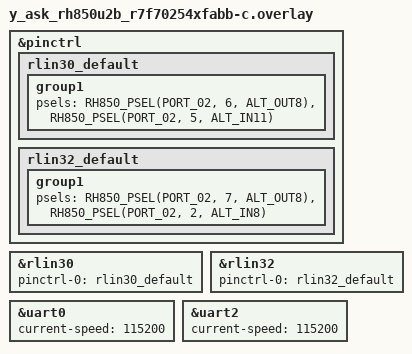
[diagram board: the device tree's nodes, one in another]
/*
 * Copyright (c) 2026 Renesas Electronics Corporation
 *
 * SPDX-License-Identifier: Apache-2.0
 */

&pinctrl {
	rlin30_default: rlin30_default {
		group1 {
			psels = <RH850_PSEL(PORT_02, 6, ALT_OUT8)>,
				<RH850_PSEL(PORT_02, 5, ALT_IN11)>;
		};
	};

	rlin32_default: rlin32_default {
		group1 {
			psels = <RH850_PSEL(PORT_02, 7, ALT_OUT8)>,
				<RH850_PSEL(PORT_02, 2, ALT_IN8)>;
		};
	};
};

&rlin30 {
	pinctrl-0 = <&rlin30_default>;
	pinctrl-names = "default";
	status = "okay";
};

&rlin32 {
	pinctrl-0 = <&rlin32_default>;
	pinctrl-names = "default";
	status = "okay";
};

dut: &uart0 {
	status = "okay";
	current-speed = <115200>;
};

dut_aux: &uart2 {
	status = "okay";
	current-speed = <115200>;
};
